AUTOSAR XML (schema 4-2-2)
package /Components
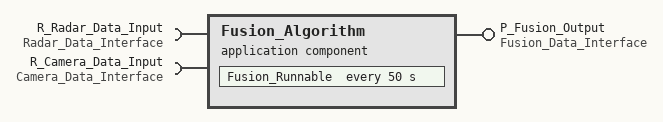
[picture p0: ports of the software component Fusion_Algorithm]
  application sw component type Fusion_Algorithm
    provide port P_Fusion_Output: provided-interface=Fusion_Data_Interface
    require port R_Radar_Data_Input: required-interface=Radar_Data_Interface
    require port R_Camera_Data_Input: required-interface=Camera_Data_Interface
    behavior Fusion_Algorithm_Internal_Behavior
      data received event Radar_Data_Received: start-on-event=Fusion_Runnable
      data received event Camera_Data_Received: start-on-event=Fusion_Runnable
      data send completed event Fusion_Data_Sent: start-on-event=Fusion_Runnable, event-source=VARIABLE-ACCESS
      timing event Fusion_Timer: start-on-event=Fusion_Runnable, period=50
      runnable Fusion_Runnable: minimum-start-interval=50, symbol=FusionAlg
        data-receive-point-by-values:
          access Radar_Data_Input_Variable: accessed-variable={autosar-variable-in-impl-datatype={port-prototype=R_Radar_Data_Input, target-data-prototype=Radar_Data}, autosar-variable=R_Radar_Data_Input.Radar_Data}
          access Camera_Data_Input_Variable: accessed-variable={autosar-variable-in-impl-datatype={port-prototype=R_Camera_Data_Input, target-data-prototype=Camera_Image}, autosar-variable=R_Camera_Data_Input.Camera_Image}
        data-send-points:
          access Fused_Data_Output_Variable: accessed-variable={autosar-variable-in-impl-datatype={port-prototype=P_Fusion_Output, target-data-prototype=Fused_Data}, autosar-variable=P_Fusion_Output.Fused_Data}
